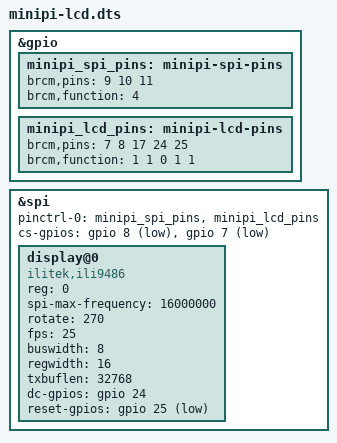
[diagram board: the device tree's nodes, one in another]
// The 3.5" 480x320 screen, on a ribbon from the Pi's pins (lcdwiki MPI3501, a copy of the
// Waveshare 3.5" (A)). Display: ILI9486 behind 16-bit shift registers, on SPI0 CE0.
// Touch: XPT2046 on CE1 (unused). Pins: DC = GPIO24, RESET = GPIO25, touch IRQ = GPIO17.
// The old 3.2" screen's version is minipi-lcd-3.2in.dts.
/dts-v1/;
/plugin/;

&gpio {
	minipi_spi_pins: minipi-spi-pins {
		brcm,pins = <9 10 11>;
		brcm,function = <4>;		/* MISO, MOSI, SCLK on SPI0 */
	};
	minipi_lcd_pins: minipi-lcd-pins {
		brcm,pins = <7 8 17 24 25>;
		brcm,function = <1 1 0 1 1>;	/* 17 in, the rest out */
	};
};

&spi {
	status = "okay";
	pinctrl-names = "default";
	pinctrl-0 = <&minipi_spi_pins &minipi_lcd_pins>;
	/* Chip selects as plain GPIOs: the mainline driver can't take the native ones (-EPROBE_DEFER). */
	cs-gpios = <&gpio 8 1>, <&gpio 7 1>;
	#address-cells = <1>;
	#size-cells = <0>;

	display@0 {
		compatible = "ilitek,ili9486";
		reg = <0>;
		spi-max-frequency = <16000000>;
		rotate = <270>;	/* upright in the case, with the ribbon leaving at the bottom edge */
		fps = <25>;
		buswidth = <8>;
		regwidth = <16>;		/* the shift registers take 16 bits per command */
		txbuflen = <32768>;
		dc-gpios = <&gpio 24 0>;	/* active high */
		reset-gpios = <&gpio 25 1>;	/* active low */
	};
};
